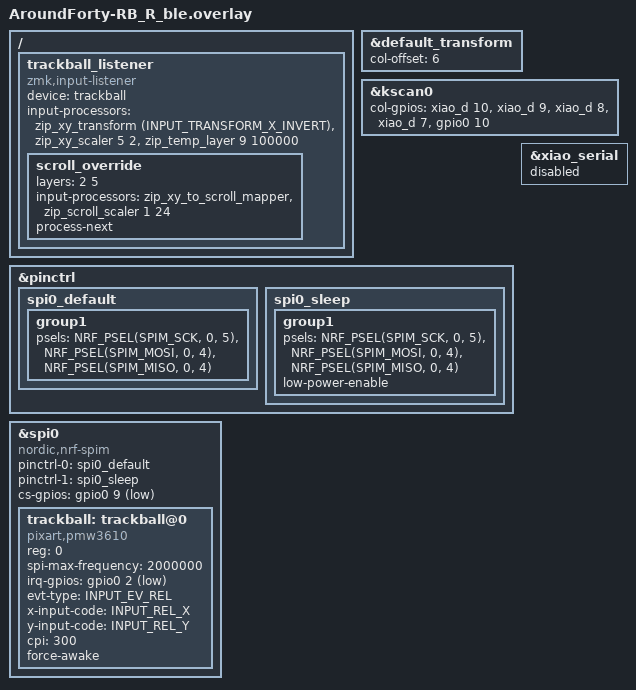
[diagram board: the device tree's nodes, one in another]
#include "../../common/AroundForty-RB.dtsi"
#include <input/processors.dtsi>                                 /* # input processor定義を使う（ここは必ずファイル先頭へ） */
#include <zephyr/dt-bindings/input/input-event-codes.h>
#include <dt-bindings/zmk/input_transform.h>


&default_transform {
    col-offset = <6>;
};

&kscan0 {
        col-gpios
            = <&xiao_d 10 GPIO_ACTIVE_HIGH>
            , <&xiao_d 9 GPIO_ACTIVE_HIGH> 
            , <&xiao_d 8 GPIO_ACTIVE_HIGH> 
            , <&xiao_d 7 GPIO_ACTIVE_HIGH> 
            , <&gpio0 10 GPIO_ACTIVE_HIGH>
            ;
};

/ {
    trackball_listener {
        compatible = "zmk,input-listener";
        device = <&trackball>;
        //input-pro/cessors = <&zip_temp_layer 9 100000>;

        // リスナー：X・Y両方をリスナーで処理
        input-processors = <&zip_xy_transform (INPUT_TRANSFORM_X_INVERT)>,
                          <&zip_xy_scaler 5 2>,
                          <&zip_temp_layer 9 100000>;

        scroll_override {                                        /* # レイヤー中だけスクロール化（対応しているfork/版のみ有効） */
            layers = <2 5>;                                      /* # スクロール化したいレイヤー番号 */
            input-processors = <&zip_xy_to_scroll_mapper>, <&zip_scroll_scaler 1 24>;       /* # XY移動→スクロールに変換 */
            process-next;                                        /* # B：この後もベース（zip_temp_layer）を続けて適用 */
        };                                                       /* # override終わり */
    };
};

&pinctrl {
    spi0_default: spi0_default {
        group1 {
            psels = <NRF_PSEL(SPIM_SCK, 0, 5)>,
                <NRF_PSEL(SPIM_MOSI, 0, 4)>,
                <NRF_PSEL(SPIM_MISO, 0, 4)>;
        };
    };

    spi0_sleep: spi0_sleep {
        group1 {
            psels = <NRF_PSEL(SPIM_SCK, 0, 5)>,
                <NRF_PSEL(SPIM_MOSI, 0, 4)>,
                <NRF_PSEL(SPIM_MISO, 0, 4)>;
            low-power-enable;
        };
    };
};

&xiao_serial { status = "disabled"; };

&spi0 {
    status = "okay";
    compatible = "nordic,nrf-spim";
    pinctrl-0 = <&spi0_default>;
    pinctrl-1 = <&spi0_sleep>;
    pinctrl-names = "default", "sleep";
    cs-gpios = <&gpio0 9 GPIO_ACTIVE_LOW>;

    trackball: trackball@0 {
        status = "okay";
        compatible = "pixart,pmw3610";
        reg = <0>;
        spi-max-frequency = <2000000>;
        irq-gpios = <&gpio0 2 (GPIO_ACTIVE_LOW | GPIO_PULL_UP)>;
        //automouse-layer = <8>;
        //scroll-layers = <10>;

        evt-type = <INPUT_EV_REL>;
        x-input-code = <INPUT_REL_X>;
        y-input-code = <INPUT_REL_Y>;

        /* 旧 .conf からの移行例（必要に応じてコメントアウトを外して使用） */
        cpi = <300>;       /* 旧: CONFIG_PMW3610_CPI=700 */
        force-awake;
        //invert-x;          /* 旧: CONFIG_PMW3610_INVERT_X=y */
        //invert-y;          /* 旧: CONFIG_PMW3610_INVERT_Y=y */
    };
};


